AUTOSAR XML (schema 4-2-2)
package /ComponentTypes
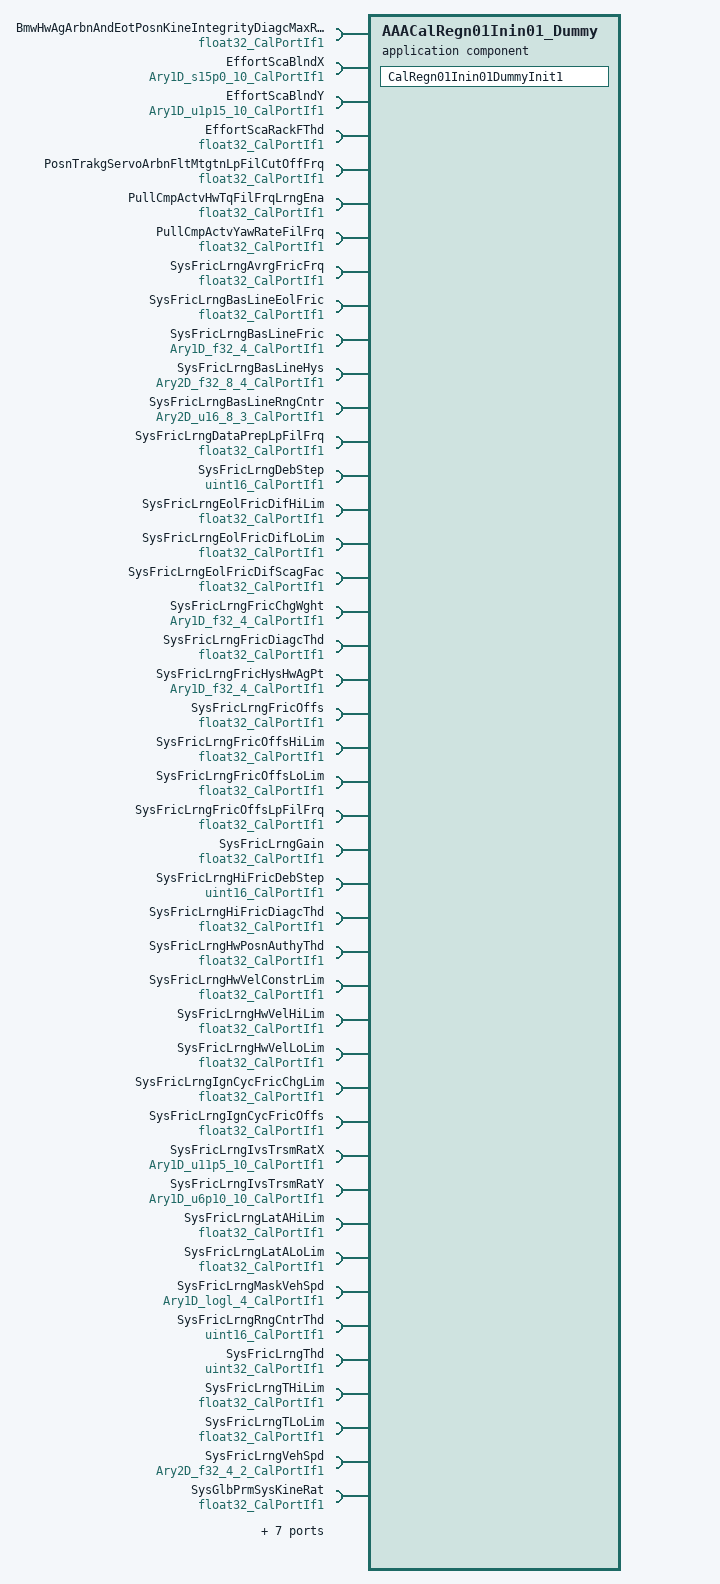
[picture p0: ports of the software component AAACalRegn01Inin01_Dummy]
  application sw component type AAACalRegn01Inin01_Dummy
    51 x require port:
      BmwHwAgArbnAndEotPosnKineIntegrityDiagcMaxRackLim: parameter-require-com-spec{init-value=2100, parameter=Val}, required-interface=float32_CalPortIf1
      EffortScaBlndX: parameter-require-com-spec{init-value=[0, 20, 40, 60, 80, 100, 120, 140, 160, 180], parameter=Ary1D}, required-interface=Ary1D_s15p0_10_CalPortIf1
      EffortScaBlndY: parameter-require-com-spec{init-value=[0, 3641, 7281, 10922, 14562, 18206, 21846, 25487, 29127, 32768], parameter=Ary1D}, required-interface=Ary1D_u1p15_10_CalPortIf1
      EffortScaRackFThd: parameter-require-com-spec{init-value=500, parameter=Val}, required-interface=float32_CalPortIf1
      PosnTrakgServoArbnFltMtgtnLpFilCutOffFrq: parameter-require-com-spec{init-value=1, parameter=Val}, required-interface=float32_CalPortIf1
      PullCmpActvHwTqFilFrqLrngEna: parameter-require-com-spec{init-value=20, parameter=Val}, required-interface=float32_CalPortIf1
      PullCmpActvYawRateFilFrq: parameter-require-com-spec{init-value=3, parameter=Val}, required-interface=float32_CalPortIf1
      SysFricLrngAvrgFricFrq: parameter-require-com-spec{init-value=0.1, parameter=Val}, required-interface=float32_CalPortIf1
      SysFricLrngBasLineEolFric: parameter-require-com-spec{init-value=0, parameter=Val}, required-interface=float32_CalPortIf1
      SysFricLrngBasLineFric: parameter-require-com-spec{init-value=[0, 0, 0, 0], parameter=Ary1D}, required-interface=Ary1D_f32_4_CalPortIf1
      SysFricLrngBasLineHys: parameter-require-com-spec{init-value=8 x [0, 0, 0, 0], parameter=Ary2D}, required-interface=Ary2D_f32_8_4_CalPortIf1
      SysFricLrngBasLineRngCntr: parameter-require-com-spec{init-value=8 x [0, 0, 0], parameter=Ary2D}, required-interface=Ary2D_u16_8_3_CalPortIf1
      SysFricLrngDataPrepLpFilFrq: parameter-require-com-spec{init-value=30, parameter=Val}, required-interface=float32_CalPortIf1
      SysFricLrngDebStep: parameter-require-com-spec{init-value=656, parameter=Val}, required-interface=uint16_CalPortIf1
      SysFricLrngEolFricDifHiLim: parameter-require-com-spec{init-value=1, parameter=Val}, required-interface=float32_CalPortIf1
      SysFricLrngEolFricDifLoLim: parameter-require-com-spec{init-value=-1, parameter=Val}, required-interface=float32_CalPortIf1
      SysFricLrngEolFricDifScagFac: parameter-require-com-spec{init-value=0.8, parameter=Val}, required-interface=float32_CalPortIf1
      SysFricLrngFricChgWght: parameter-require-com-spec{init-value=[1, 1, 1, 1], parameter=Ary1D}, required-interface=Ary1D_f32_4_CalPortIf1
      SysFricLrngFricDiagcThd: parameter-require-com-spec{init-value=15, parameter=Val}, required-interface=float32_CalPortIf1
      SysFricLrngFricHysHwAgPt: parameter-require-com-spec{init-value=[-15, -5, 5, 15], parameter=Ary1D}, required-interface=Ary1D_f32_4_CalPortIf1
      SysFricLrngFricOffs: parameter-require-com-spec{init-value=0, parameter=Val}, required-interface=float32_CalPortIf1
      SysFricLrngFricOffsHiLim: parameter-require-com-spec{init-value=1, parameter=Val}, required-interface=float32_CalPortIf1
      SysFricLrngFricOffsLoLim: parameter-require-com-spec{init-value=-1, parameter=Val}, required-interface=float32_CalPortIf1
      SysFricLrngFricOffsLpFilFrq: parameter-require-com-spec{init-value=4, parameter=Val}, required-interface=float32_CalPortIf1
      SysFricLrngGain: parameter-require-com-spec{init-value=0.2, parameter=Val}, required-interface=float32_CalPortIf1
      SysFricLrngHiFricDebStep: parameter-require-com-spec{init-value=656, parameter=Val}, required-interface=uint16_CalPortIf1
      SysFricLrngHiFricDiagcThd: parameter-require-com-spec{init-value=30, parameter=Val}, required-interface=float32_CalPortIf1
      SysFricLrngHwPosnAuthyThd: parameter-require-com-spec{init-value=0.98, parameter=Val}, required-interface=float32_CalPortIf1
      SysFricLrngHwVelConstrLim: parameter-require-com-spec{init-value=360, parameter=Val}, required-interface=float32_CalPortIf1
      SysFricLrngHwVelHiLim: parameter-require-com-spec{init-value=180, parameter=Val}, required-interface=float32_CalPortIf1
      SysFricLrngHwVelLoLim: parameter-require-com-spec{init-value=10, parameter=Val}, required-interface=float32_CalPortIf1
      SysFricLrngIgnCycFricChgLim: parameter-require-com-spec{init-value=3, parameter=Val}, required-interface=float32_CalPortIf1
      SysFricLrngIgnCycFricOffs: parameter-require-com-spec{init-value=3, parameter=Val}, required-interface=float32_CalPortIf1
      SysFricLrngIvsTrsmRatX: parameter-require-com-spec{init-value=[0, 960, 1920, 2880, 3840, 5760, 8640, 11520, 14400, 17280], parameter=Ary1D}, required-interface=Ary1D_u11p5_10_CalPortIf1
      SysFricLrngIvsTrsmRatY: parameter-require-com-spec{init-value=10 x 24269, parameter=Ary1D}, required-interface=Ary1D_u6p10_10_CalPortIf1
      SysFricLrngLatAHiLim: parameter-require-com-spec{init-value=10, parameter=Val}, required-interface=float32_CalPortIf1
      SysFricLrngLatALoLim: parameter-require-com-spec{init-value=0, parameter=Val}, required-interface=float32_CalPortIf1
      SysFricLrngMaskVehSpd: parameter-require-com-spec{init-value=[1, 1, 1, 1], parameter=Ary1D}, required-interface=Ary1D_logl_4_CalPortIf1
      SysFricLrngRngCntrThd: parameter-require-com-spec{init-value=65534, parameter=Val}, required-interface=uint16_CalPortIf1
      SysFricLrngThd: parameter-require-com-spec{init-value=1, parameter=Val}, required-interface=uint32_CalPortIf1
      SysFricLrngTHiLim: parameter-require-com-spec{init-value=100, parameter=Val}, required-interface=float32_CalPortIf1
      SysFricLrngTLoLim: parameter-require-com-spec{init-value=0, parameter=Val}, required-interface=float32_CalPortIf1
      SysFricLrngVehSpd: parameter-require-com-spec{init-value=[[0, 5], [60, 80], [80, 100], [100, 120]], parameter=Ary2D}, required-interface=Ary2D_f32_4_2_CalPortIf1
      SysGlbPrmSysKineRat: parameter-require-com-spec{init-value=22, parameter=Val}, required-interface=float32_CalPortIf1
      SysGlbPrmVehSpdBilnrSeln: parameter-require-com-spec{init-value=[0, 640, 1920, 3840, 7680, 10240, 12800, 15360, 19200, 23040, 25600, 28160], parameter=Ary1D}, required-interface=Ary1D_u9p7_12_CalPortIf1
      SysKineAndEffMotAgToRackPosRatScaY: parameter-require-com-spec{init-value=[1233, 1237, 1241, 1245, 1249, 1253, 1257, 1262, 1262, 1262, 1262, 1262, 1262, 1262, 1257, 1253, 1249, 1245, 1241, 1237, 1233], parameter=Ary1D}, required-interface=Ary1D_u4p12_21_CalPortIf1
      SysKineAndEffPinionAgToRackPosRatScaY: parameter-require-com-spec{init-value=[17592, 17592, 17592, 17285, 16589, 15770, 14930, 14213, 13926, 13681, 13681, 13681, 13926, 14213, 14930, 15770, 16589, 17285, 17592, 17592, 17592], parameter=Ary1D}, required-interface=Ary1D_u5p11_21_CalPortIf1
      SysKineAndEffPinionToRackEffScaY: parameter-require-com-spec{init-value=[29491, 29655, 29819, 29983, 30147, 30147, 30147, 30147, 30147, 30147, 30147, 30147, 30147, 30147, 30147, 30147, 30147, 29983, 29819, 29655, 29491], parameter=Ary1D}, required-interface=Ary1D_u1p15_21_CalPortIf1
      SysKineAndEffRoadWhlFromRackPosScaY: parameter-require-com-spec{init-value=[-5939, -5300, -4678, -4063, -3465, -2867, -2277, -1704, -1139, -565, 0, 565, 1139, 1704, 2277, 2867, 3465, 4063, 4678, 5300, 5939], parameter=Ary1D}, required-interface=Ary1D_s2p13_21_CalPortIf1
      SysKineAndEffSteerArmLenFromRackPosScaY: parameter-require-com-spec{init-value=[4522, 4555, 4588, 4620, 4653, 4686, 4719, 4719, 4719, 4719, 4719, 4719, 4719, 4719, 4719, 4686, 4653, 4620, 4588, 4555, 4522], parameter=Ary1D}, required-interface=Ary1D_u1p15_21_CalPortIf1
      TunSelnAuthyVehSpdX: parameter-require-com-spec{init-value=[0, 12800, 25600, 38400, 51200, 65408], parameter=Ary1D}, required-interface=Ary1D_u9p7_6_CalPortIf1
    behavior AAACalRegn01Inin01_Dummy_InternalBehavior: supports-multiple-instantiation=true
      init event AAACalRegn01Inin01_Dummy_InitEvent: start-on-event=CalRegn01Inin01DummyInit1
      runnable CalRegn01Inin01DummyInit1
  swc implementation AAACalRegn01Inin00_Dummy_Implementation: behavior=AAACalRegn01Inin01_Dummy_InternalBehavior
    code-descriptors:
      code Default: artifact-descriptors=autosar-engineering-object={short-label=Default, category=SWSRC}
